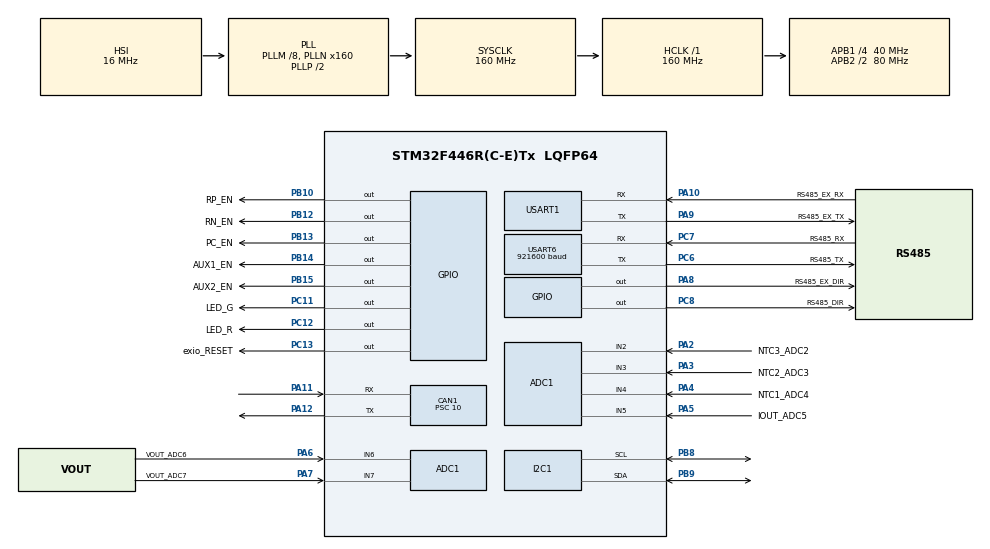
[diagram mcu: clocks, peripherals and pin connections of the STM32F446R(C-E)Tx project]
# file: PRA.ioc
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ADC1.Channel-0\#ChannelRegularConversion=ADC_CHANNEL_2
ADC1.Channel-1\#ChannelRegularConversion=ADC_CHANNEL_3
ADC1.Channel-2\#ChannelRegularConversion=ADC_CHANNEL_4
ADC1.Channel-3\#ChannelRegularConversion=ADC_CHANNEL_5
ADC1.Channel-4\#ChannelRegularConversion=ADC_CHANNEL_6
ADC1.Channel-5\#ChannelRegularConversion=ADC_CHANNEL_7
ADC1.ContinuousConvMode=ENABLE
ADC1.DMAContinuousRequests=ENABLE
ADC1.EOCSelection=ADC_EOC_SINGLE_CONV
ADC1.NbrOfConversion=6
ADC1.NbrOfConversionFlag=1
ADC1.Rank-0\#ChannelRegularConversion=1
ADC1.Rank-1\#ChannelRegularConversion=2
ADC1.Rank-2\#ChannelRegularConversion=3
ADC1.Rank-3\#ChannelRegularConversion=4
ADC1.Rank-4\#ChannelRegularConversion=5
ADC1.Rank-5\#ChannelRegularConversion=6
ADC1.SamplingTime-0\#ChannelRegularConversion=ADC_SAMPLETIME_480CYCLES
ADC1.SamplingTime-1\#ChannelRegularConversion=ADC_SAMPLETIME_480CYCLES
ADC1.SamplingTime-2\#ChannelRegularConversion=ADC_SAMPLETIME_480CYCLES
ADC1.SamplingTime-3\#ChannelRegularConversion=ADC_SAMPLETIME_15CYCLES
ADC1.SamplingTime-4\#ChannelRegularConversion=ADC_SAMPLETIME_15CYCLES
ADC1.SamplingTime-5\#ChannelRegularConversion=ADC_SAMPLETIME_15CYCLES
ADC1.ScanConvMode=ENABLE
ADC1.master=1
CAN1.BS1=CAN_BS1_11TQ
CAN1.BS2=CAN_BS2_4TQ
CAN1.CalculateBaudRate=250000
CAN1.CalculateTimeBit=4000
CAN1.CalculateTimeQuantum=250.0
CAN1.Mode=CAN_MODE_NORMAL
CAN1.Prescaler=10
CAN1.SJW=CAN_SJW_4TQ
Dma.ADC1.2.Direction=DMA_PERIPH_TO_MEMORY
Dma.ADC1.2.FIFOMode=DMA_FIFOMODE_DISABLE
Dma.ADC1.2.Instance=DMA2_Stream0
Dma.ADC1.2.MemDataAlignment=DMA_MDATAALIGN_HALFWORD
Dma.ADC1.2.MemInc=DMA_MINC_ENABLE
Dma.ADC1.2.Mode=DMA_CIRCULAR
Dma.ADC1.2.PeriphDataAlignment=DMA_PDATAALIGN_HALFWORD
Dma.ADC1.2.PeriphInc=DMA_PINC_DISABLE
Dma.ADC1.2.Priority=DMA_PRIORITY_LOW
Dma.Request0=USART6_RX
Dma.Request1=USART6_TX
Dma.Request2=ADC1
Dma.USART6_RX.0.Direction=DMA_PERIPH_TO_MEMORY
Dma.USART6_RX.0.FIFOMode=DMA_FIFOMODE_DISABLE
Dma.USART6_RX.0.Instance=DMA2_Stream1
Dma.USART6_RX.0.MemDataAlignment=DMA_MDATAALIGN_BYTE
Dma.USART6_RX.0.MemInc=DMA_MINC_ENABLE
Dma.USART6_RX.0.Mode=DMA_CIRCULAR
Dma.USART6_RX.0.PeriphDataAlignment=DMA_PDATAALIGN_BYTE
Dma.USART6_RX.0.PeriphInc=DMA_PINC_DISABLE
Dma.USART6_RX.0.Priority=DMA_PRIORITY_LOW
Dma.USART6_TX.1.Direction=DMA_MEMORY_TO_PERIPH
Dma.USART6_TX.1.FIFOMode=DMA_FIFOMODE_DISABLE
Dma.USART6_TX.1.Instance=DMA2_Stream6
Dma.USART6_TX.1.MemDataAlignment=DMA_MDATAALIGN_BYTE
Dma.USART6_TX.1.MemInc=DMA_MINC_ENABLE
Dma.USART6_TX.1.Mode=DMA_NORMAL
Dma.USART6_TX.1.PeriphDataAlignment=DMA_PDATAALIGN_BYTE
Dma.USART6_TX.1.PeriphInc=DMA_PINC_DISABLE
Dma.USART6_TX.1.Priority=DMA_PRIORITY_LOW
FREERTOS.Tasks01=defaultTask,24,512,StartDefaultTask,Default,NULL,Dynamic,NULL,NULL;rs485Task,8,512,Start_rs485,Default,NULL,Dynamic,NULL,NULL;controlTask,8,1024,StartControl,Default,NULL,Dynamic,NULL,NULL;systemTask,8,512,StartSystem,Default,NULL,Dynamic,NULL,NULL;can1Task,8,512,Start_can1,Default,NULL,Dynamic,NULL,NULL
FREERTOS.configTOTAL_HEAP_SIZE=30720
FREERTOS.configUSE_NEWLIB_REENTRANT=1
I2C1.I2C_Mode=I2C_Standard
Mcu.Family=STM32F4
Mcu.Name=STM32F446R(C-E)Tx
Mcu.Package=LQFP64
NVIC.ADC_IRQn=true\:5\:0\:false\:false\:true\:true\:true\:true\:true
NVIC.CAN1_RX0_IRQn=true\:5\:0\:false\:false\:true\:true\:true\:true\:true
NVIC.CAN1_SCE_IRQn=true\:5\:0\:false\:false\:true\:true\:true\:true\:true
NVIC.DMA2_Stream0_IRQn=true\:5\:0\:false\:false\:true\:true\:false\:true\:true
NVIC.DMA2_Stream1_IRQn=true\:5\:0\:false\:false\:true\:true\:false\:true\:true
NVIC.DMA2_Stream6_IRQn=true\:5\:0\:false\:false\:true\:true\:false\:true\:true
NVIC.PriorityGroup=NVIC_PRIORITYGROUP_4
NVIC.TIM6_DAC_IRQn=true\:15\:0\:false\:false\:true\:false\:false\:true\:true
NVIC.TimeBase=TIM6_DAC_IRQn
NVIC.TimeBaseIP=TIM6
NVIC.USART6_IRQn=true\:5\:0\:false\:false\:true\:true\:true\:true\:true
PA10.GPIO_Label=RS485_EX_RX
PA10.Mode=Asynchronous
PA10.Signal=USART1_RX
PA11.Mode=CAN_Activate
PA11.Signal=CAN1_RX
PA12.Mode=CAN_Activate
PA12.Signal=CAN1_TX
PA13.Mode=Trace_Asynchronous_SW
PA13.Signal=SYS_JTMS-SWDIO
PA14.Mode=Trace_Asynchronous_SW
PA14.Signal=SYS_JTCK-SWCLK
PA2.GPIO_Label=NTC3_ADC2
PA2.Signal=ADCx_IN2
PA3.GPIO_Label=NTC2_ADC3
PA3.Signal=ADCx_IN3
PA4.GPIO_Label=NTC1_ADC4
PA4.Signal=ADCx_IN4
PA5.GPIO_Label=IOUT_ADC5
PA5.Signal=ADCx_IN5
PA6.GPIO_Label=VOUT_ADC6
PA6.Signal=ADCx_IN6
PA7.GPIO_Label=VOUT_ADC7
PA7.Signal=ADCx_IN7
PA8.GPIO_Label=RS485_EX_DIR
PA8.Signal=GPIO_Output
PA9.GPIO_Label=RS485_EX_TX
PA9.Mode=Asynchronous
PA9.Signal=USART1_TX
PB10.GPIO_Label=RP_EN
PB10.Signal=GPIO_Output
PB12.GPIO_Label=RN_EN
PB12.Signal=GPIO_Output
PB13.GPIO_Label=PC_EN
PB13.Signal=GPIO_Output
PB14.GPIO_Label=AUX1_EN
PB14.Signal=GPIO_Output
PB15.GPIO_Label=AUX2_EN
PB15.Signal=GPIO_Output
PB3.Mode=Trace_Asynchronous_SW
PB3.Signal=SYS_JTDO-SWO
PB8.Mode=I2C
PB8.Signal=I2C1_SCL
PB9.Mode=I2C
PB9.Signal=I2C1_SDA
PC11.GPIO_Label=LED_G
PC11.Signal=GPIO_Output
PC12.GPIO_Label=LED_R
PC12.Signal=GPIO_Output
PC13.GPIO_Label=exio_RESET
PC13.Signal=GPIO_Output
PC6.GPIO_Label=RS485_TX
PC6.Mode=Asynchronous
PC6.Signal=USART6_TX
PC7.GPIO_Label=RS485_RX
PC7.Mode=Asynchronous
PC7.Signal=USART6_RX
PC8.GPIO_Label=RS485_DIR
PC8.Signal=GPIO_Output
ProjectManager.HeapSize=0x200
ProjectManager.StackSize=0x400
ProjectManager.TargetToolchain=STM32CubeIDE
RCC.AHBFreq_Value=160000000
RCC.APB1CLKDivider=RCC_HCLK_DIV4
RCC.APB1Freq_Value=40000000
RCC.APB1TimFreq_Value=80000000
RCC.APB2CLKDivider=RCC_HCLK_DIV2
RCC.APB2Freq_Value=80000000
RCC.APB2TimFreq_Value=160000000
RCC.CortexFreq_Value=160000000
RCC.HCLKFreq_Value=160000000
RCC.PLLM=8
RCC.PLLN=160
RCC.SYSCLKFreq_VALUE=160000000
RCC.SYSCLKSource=RCC_SYSCLKSOURCE_PLLCLK
RCC.USBFreq_Value=160000000
RCC.VCOOutputFreq_Value=320000000
SH.ADCx_IN2.0=ADC1_IN2,IN2
SH.ADCx_IN3.0=ADC1_IN3,IN3
SH.ADCx_IN4.0=ADC1_IN4,IN4
SH.ADCx_IN5.0=ADC1_IN5,IN5
SH.ADCx_IN6.0=ADC1_IN6,IN6
SH.ADCx_IN7.0=ADC1_IN7,IN7
USART1.VirtualMode=VM_ASYNC
USART6.BaudRate=921600
USART6.VirtualMode=VM_ASYNC
VP_FREERTOS_VS_CMSIS_V2.Mode=CMSIS_V2
VP_SYS_VS_tim6.Mode=TIM6
board=custom

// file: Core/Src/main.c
/* USER CODE BEGIN Header */
/**
  ******************************************************************************
  * @file           : main.c
  * @brief          : Main program body
  ******************************************************************************
  * @attention
  *
  * Copyright (c) 2025 STMicroelectronics.
  * All rights reserved.
  *
  * This software is licensed under terms that can be found in the LICENSE file
  * in the root directory of this software component.
  * If no LICENSE file comes with this software, it is provided AS-IS.
  *
  ******************************************************************************
  */
/* USER CODE END Header */
#include "main.h"
#include "cmsis_os.h"

/* USER CODE BEGIN Includes */

#include "rd_common.h"
#include "rd_define.h"

#include "rd_uart.h"
#include "rd_peripheral.h"
#include "rd_system.h"      /* RD_SYSTEM_INIT, RD_TASK_RS485, 전역 객체 (Step4) */
#include "rd_can_bms.h"
/* USER CODE END Includes */

ADC_HandleTypeDef hadc1;
DMA_HandleTypeDef hdma_adc1;

CAN_HandleTypeDef hcan1;

I2C_HandleTypeDef hi2c1;

UART_HandleTypeDef huart1;
UART_HandleTypeDef huart6;
DMA_HandleTypeDef hdma_usart6_rx;
DMA_HandleTypeDef hdma_usart6_tx;

/* Definitions for defaultTask */
osThreadId_t defaultTaskHandle;
const osThreadAttr_t defaultTask_attributes = {
  .name = "defaultTask",
  .stack_size = 512 * 4,
  .priority = (osPriority_t) osPriorityNormal,
};
/* Definitions for rs485Task */
osThreadId_t rs485TaskHandle;
const osThreadAttr_t rs485Task_attributes = {
  .name = "rs485Task",
  .stack_size = 512 * 4,
  .priority = (osPriority_t) osPriorityLow,
};
/* Definitions for controlTask */
osThreadId_t controlTaskHandle;
const osThreadAttr_t controlTask_attributes = {
  .name = "controlTask",
  .stack_size = 1024 * 4,
  .priority = (osPriority_t) osPriorityLow,
};
/* Definitions for systemTask */
osThreadId_t systemTaskHandle;
const osThreadAttr_t systemTask_attributes = {
  .name = "systemTask",
  .stack_size = 512 * 4,
  .priority = (osPriority_t) osPriorityLow,
};
/* Definitions for can1Task */
osThreadId_t can1TaskHandle;
const osThreadAttr_t can1Task_attributes = {
  .name = "can1Task",
  .stack_size = 512 * 4,
  .priority = (osPriority_t) osPriorityLow,
};

void SystemClock_Config(void);
static void MX_GPIO_Init(void);
static void MX_DMA_Init(void);
static void MX_ADC1_Init(void);
static void MX_CAN1_Init(void);
static void MX_USART1_UART_Init(void);
static void MX_USART6_UART_Init(void);
static void MX_I2C1_Init(void);
void StartDefaultTask(void *argument);
void Start_rs485(void *argument);
void StartControl(void *argument);
void StartSystem(void *argument);
void Start_can1(void *argument);

int main(void)
{

  /* MCU Configuration--------------------------------------------------------*/

  /* Reset of all peripherals, Initializes the Flash interface and the Systick. */
  HAL_Init();

  /* Configure the system clock */
  SystemClock_Config();

  /* Initialize all configured peripherals */
  MX_GPIO_Init();
  MX_DMA_Init();
  MX_ADC1_Init();
  MX_CAN1_Init();
  MX_USART1_UART_Init();
  MX_USART6_UART_Init();
  MX_I2C1_Init();
  /* USER CODE BEGIN 2 */
  RD_SYSTEM_INIT();   /* UART 바인딩 + 레지스터 맵/패킷 채널 INIT (스케줄러 시작 전 1회) */
  /* USER CODE END 2 */

  /* Init scheduler */
  osKernelInitialize();

  /* Create the thread(s) */
  /* creation of defaultTask */
  defaultTaskHandle = osThreadNew(StartDefaultTask, NULL, &defaultTask_attributes);

  /* creation of rs485Task */
  rs485TaskHandle = osThreadNew(Start_rs485, NULL, &rs485Task_attributes);

  /* creation of controlTask */
  controlTaskHandle = osThreadNew(StartControl, NULL, &controlTask_attributes);

  /* creation of systemTask */
  systemTaskHandle = osThreadNew(StartSystem, NULL, &systemTask_attributes);

  /* creation of can1Task */
  can1TaskHandle = osThreadNew(Start_can1, NULL, &can1Task_attributes);

  /* Start scheduler */
  osKernelStart();

  /* We should never get here as control is now taken by the scheduler */

  /* Infinite loop */
  while (1)
  {

  }
}

void SystemClock_Config(void)
{
  RCC_OscInitTypeDef RCC_OscInitStruct = {0};
  RCC_ClkInitTypeDef RCC_ClkInitStruct = {0};

  /** Configure the main internal regulator output voltage
  */
  __HAL_RCC_PWR_CLK_ENABLE();
  __HAL_PWR_VOLTAGESCALING_CONFIG(PWR_REGULATOR_VOLTAGE_SCALE1);

  /** Initializes the RCC Oscillators according to the specified parameters
  * in the RCC_OscInitTypeDef structure.
  */
  RCC_OscInitStruct.OscillatorType = RCC_OSCILLATORTYPE_HSI;
  RCC_OscInitStruct.HSIState = RCC_HSI_ON;
  RCC_OscInitStruct.HSICalibrationValue = RCC_HSICALIBRATION_DEFAULT;
  RCC_OscInitStruct.PLL.PLLState = RCC_PLL_ON;
  RCC_OscInitStruct.PLL.PLLSource = RCC_PLLSOURCE_HSI;
  RCC_OscInitStruct.PLL.PLLM = 8;
  RCC_OscInitStruct.PLL.PLLN = 160;
  RCC_OscInitStruct.PLL.PLLP = RCC_PLLP_DIV2;
  RCC_OscInitStruct.PLL.PLLQ = 2;
  RCC_OscInitStruct.PLL.PLLR = 2;
  if (HAL_RCC_OscConfig(&RCC_OscInitStruct) != HAL_OK)
  {
    Error_Handler();
  }

  /** Initializes the CPU, AHB and APB buses clocks
  */
  RCC_ClkInitStruct.ClockType = RCC_CLOCKTYPE_HCLK|RCC_CLOCKTYPE_SYSCLK
                              |RCC_CLOCKTYPE_PCLK1|RCC_CLOCKTYPE_PCLK2;
  RCC_ClkInitStruct.SYSCLKSource = RCC_SYSCLKSOURCE_PLLCLK;
  RCC_ClkInitStruct.AHBCLKDivider = RCC_SYSCLK_DIV1;
  RCC_ClkInitStruct.APB1CLKDivider = RCC_HCLK_DIV4;
  RCC_ClkInitStruct.APB2CLKDivider = RCC_HCLK_DIV2;

  if (HAL_RCC_ClockConfig(&RCC_ClkInitStruct, FLASH_LATENCY_5) != HAL_OK)
  {
    Error_Handler();
  }
}

static void MX_ADC1_Init(void)
{

  ADC_ChannelConfTypeDef sConfig = {0};

  /** Configure the global features of the ADC (Clock, Resolution, Data Alignment and number of conversion)
  */
  hadc1.Instance = ADC1;
  hadc1.Init.ClockPrescaler = ADC_CLOCK_SYNC_PCLK_DIV4;
  hadc1.Init.Resolution = ADC_RESOLUTION_12B;
  hadc1.Init.ScanConvMode = ENABLE;
  hadc1.Init.ContinuousConvMode = ENABLE;
  hadc1.Init.DiscontinuousConvMode = DISABLE;
  hadc1.Init.ExternalTrigConvEdge = ADC_EXTERNALTRIGCONVEDGE_NONE;
  hadc1.Init.ExternalTrigConv = ADC_SOFTWARE_START;
  hadc1.Init.DataAlign = ADC_DATAALIGN_RIGHT;
  hadc1.Init.NbrOfConversion = 6;
  hadc1.Init.DMAContinuousRequests = ENABLE;
  hadc1.Init.EOCSelection = ADC_EOC_SINGLE_CONV;
  if (HAL_ADC_Init(&hadc1) != HAL_OK)
  {
    Error_Handler();
  }

  /** Configure for the selected ADC regular channel its corresponding rank in the sequencer and its sample time.
  */
  sConfig.Channel = ADC_CHANNEL_2;
  sConfig.Rank = 1;
  sConfig.SamplingTime = ADC_SAMPLETIME_480CYCLES;
  if (HAL_ADC_ConfigChannel(&hadc1, &sConfig) != HAL_OK)
  {
    Error_Handler();
  }

  /** Configure for the selected ADC regular channel its corresponding rank in the sequencer and its sample time.
  */
  sConfig.Channel = ADC_CHANNEL_3;
  sConfig.Rank = 2;
  if (HAL_ADC_ConfigChannel(&hadc1, &sConfig) != HAL_OK)
  {
    Error_Handler();
  }

  /** Configure for the selected ADC regular channel its corresponding rank in the sequencer and its sample time.
  */
  sConfig.Channel = ADC_CHANNEL_4;
  sConfig.Rank = 3;
  if (HAL_ADC_ConfigChannel(&hadc1, &sConfig) != HAL_OK)
  {
    Error_Handler();
  }

  /** Configure for the selected ADC regular channel its corresponding rank in the sequencer and its sample time.
  */
  sConfig.Channel = ADC_CHANNEL_5;
  sConfig.Rank = 4;
  sConfig.SamplingTime = ADC_SAMPLETIME_15CYCLES;
  if (HAL_ADC_ConfigChannel(&hadc1, &sConfig) != HAL_OK)
  {
    Error_Handler();
  }

  /** Configure for the selected ADC regular channel its corresponding rank in the sequencer and its sample time.
  */
  sConfig.Channel = ADC_CHANNEL_6;
  sConfig.Rank = 5;
  if (HAL_ADC_ConfigChannel(&hadc1, &sConfig) != HAL_OK)
  {
    Error_Handler();
  }

  /** Configure for the selected ADC regular channel its corresponding rank in the sequencer and its sample time.
  */
  sConfig.Channel = ADC_CHANNEL_7;
  sConfig.Rank = 6;
  if (HAL_ADC_ConfigChannel(&hadc1, &sConfig) != HAL_OK)
  {
    Error_Handler();
  }

}

static void MX_CAN1_Init(void)
{

  hcan1.Instance = CAN1;
  hcan1.Init.Prescaler = 10;
  hcan1.Init.Mode = CAN_MODE_NORMAL;
  hcan1.Init.SyncJumpWidth = CAN_SJW_4TQ;
  hcan1.Init.TimeSeg1 = CAN_BS1_11TQ;
  hcan1.Init.TimeSeg2 = CAN_BS2_4TQ;
  hcan1.Init.TimeTriggeredMode = DISABLE;
  hcan1.Init.AutoBusOff = DISABLE;
  hcan1.Init.AutoWakeUp = DISABLE;
  hcan1.Init.AutoRetransmission = DISABLE;
  hcan1.Init.ReceiveFifoLocked = DISABLE;
  hcan1.Init.TransmitFifoPriority = DISABLE;
  if (HAL_CAN_Init(&hcan1) != HAL_OK)
  {
    Error_Handler();
  }

}

static void MX_I2C1_Init(void)
{

  hi2c1.Instance = I2C1;
  hi2c1.Init.ClockSpeed = 100000;
  hi2c1.Init.DutyCycle = I2C_DUTYCYCLE_2;
  hi2c1.Init.OwnAddress1 = 0;
  hi2c1.Init.AddressingMode = I2C_ADDRESSINGMODE_7BIT;
  hi2c1.Init.DualAddressMode = I2C_DUALADDRESS_DISABLE;
  hi2c1.Init.OwnAddress2 = 0;
  hi2c1.Init.GeneralCallMode = I2C_GENERALCALL_DISABLE;
  hi2c1.Init.NoStretchMode = I2C_NOSTRETCH_DISABLE;
  if (HAL_I2C_Init(&hi2c1) != HAL_OK)
  {
    Error_Handler();
  }

}

static void MX_USART1_UART_Init(void)
{

  huart1.Instance = USART1;
  huart1.Init.BaudRate = 115200;
  huart1.Init.WordLength = UART_WORDLENGTH_8B;
  huart1.Init.StopBits = UART_STOPBITS_1;
  huart1.Init.Parity = UART_PARITY_NONE;
  huart1.Init.Mode = UART_MODE_TX_RX;
  huart1.Init.HwFlowCtl = UART_HWCONTROL_NONE;
  huart1.Init.OverSampling = UART_OVERSAMPLING_16;
  if (HAL_UART_Init(&huart1) != HAL_OK)
  {
    Error_Handler();
  }

}

static void MX_USART6_UART_Init(void)
{

  huart6.Instance = USART6;
  huart6.Init.BaudRate = 921600;
  huart6.Init.WordLength = UART_WORDLENGTH_8B;
  huart6.Init.StopBits = UART_STOPBITS_1;
  huart6.Init.Parity = UART_PARITY_NONE;
  huart6.Init.Mode = UART_MODE_TX_RX;
  huart6.Init.HwFlowCtl = UART_HWCONTROL_NONE;
  huart6.Init.OverSampling = UART_OVERSAMPLING_16;
  if (HAL_UART_Init(&huart6) != HAL_OK)
  {
    Error_Handler();
  }

}

static void MX_DMA_Init(void)
{

  /* DMA controller clock enable */
  __HAL_RCC_DMA2_CLK_ENABLE();

  /* DMA interrupt init */
  /* DMA2_Stream0_IRQn interrupt configuration */
  HAL_NVIC_SetPriority(DMA2_Stream0_IRQn, 5, 0);
  HAL_NVIC_EnableIRQ(DMA2_Stream0_IRQn);
  /* DMA2_Stream1_IRQn interrupt configuration */
  HAL_NVIC_SetPriority(DMA2_Stream1_IRQn, 5, 0);
  HAL_NVIC_EnableIRQ(DMA2_Stream1_IRQn);
  /* DMA2_Stream6_IRQn interrupt configuration */
  HAL_NVIC_SetPriority(DMA2_Stream6_IRQn, 5, 0);
  HAL_NVIC_EnableIRQ(DMA2_Stream6_IRQn);

}

static void MX_GPIO_Init(void)
{
  GPIO_InitTypeDef GPIO_InitStruct = {0};

  /* GPIO Ports Clock Enable */
  __HAL_RCC_GPIOC_CLK_ENABLE();
  __HAL_RCC_GPIOA_CLK_ENABLE();
  __HAL_RCC_GPIOB_CLK_ENABLE();

  /*Configure GPIO pin Output Level */
  HAL_GPIO_WritePin(GPIOC, exio_RESET_Pin|RS485_DIR_Pin|LED_G_Pin|LED_R_Pin, GPIO_PIN_RESET);

  /*Configure GPIO pin Output Level */
  HAL_GPIO_WritePin(GPIOB, RP_EN_Pin|RN_EN_Pin|PC_EN_Pin|AUX1_EN_Pin
                          |AUX2_EN_Pin, GPIO_PIN_RESET);

  /*Configure GPIO pin Output Level */
  HAL_GPIO_WritePin(RS485_EX_DIR_GPIO_Port, RS485_EX_DIR_Pin, GPIO_PIN_RESET);

  /*Configure GPIO pins : exio_RESET_Pin RS485_DIR_Pin LED_G_Pin LED_R_Pin */
  GPIO_InitStruct.Pin = exio_RESET_Pin|RS485_DIR_Pin|LED_G_Pin|LED_R_Pin;
  GPIO_InitStruct.Mode = GPIO_MODE_OUTPUT_PP;
  GPIO_InitStruct.Pull = GPIO_NOPULL;
  GPIO_InitStruct.Speed = GPIO_SPEED_FREQ_LOW;
  HAL_GPIO_Init(GPIOC, &GPIO_InitStruct);

  /*Configure GPIO pins : RP_EN_Pin RN_EN_Pin PC_EN_Pin AUX1_EN_Pin
                           AUX2_EN_Pin */
  GPIO_InitStruct.Pin = RP_EN_Pin|RN_EN_Pin|PC_EN_Pin|AUX1_EN_Pin
                          |AUX2_EN_Pin;
  GPIO_InitStruct.Mode = GPIO_MODE_OUTPUT_PP;
  GPIO_InitStruct.Pull = GPIO_NOPULL;
  GPIO_InitStruct.Speed = GPIO_SPEED_FREQ_LOW;
  HAL_GPIO_Init(GPIOB, &GPIO_InitStruct);

  /*Configure GPIO pin : RS485_EX_DIR_Pin */
  GPIO_InitStruct.Pin = RS485_EX_DIR_Pin;
  GPIO_InitStruct.Mode = GPIO_MODE_OUTPUT_PP;
  GPIO_InitStruct.Pull = GPIO_NOPULL;
  GPIO_InitStruct.Speed = GPIO_SPEED_FREQ_LOW;
  HAL_GPIO_Init(RS485_EX_DIR_GPIO_Port, &GPIO_InitStruct);

}

void StartDefaultTask(void *argument)
{
  /* USER CODE BEGIN 5 */
  RD_TASK_DEFAULT();
  /* USER CODE END 5 */
}

void Start_rs485(void *argument)
{
  /* USER CODE BEGIN Start_rs485 */
  RD_TASK_RS485();   /* 내부 init + 이벤트 for(;;) 루프 (ECU/DPC_B/PRA 구조) */
  /* USER CODE END Start_rs485 */
}

void StartControl(void *argument)
{
  /* USER CODE BEGIN StartControl */
  /* Infinite loop */
	RD_TASK_CONTROL();
  /* USER CODE END StartControl */
}

void StartSystem(void *argument)
{
  /* USER CODE BEGIN StartSystem */
  RD_TASK_SYSTEM();   /* 10ms Checker/EVALUATE/PUBLISH (내부 for(;;)) — Step6 */
  /* USER CODE END StartSystem */
}

void Start_can1(void *argument)
{
  /* USER CODE BEGIN Start_can1 */
  RD_TASK_CAN();
  /* USER CODE END Start_can1 */
}

void HAL_TIM_PeriodElapsedCallback(TIM_HandleTypeDef *htim)
{
  if (htim->Instance == TIM6)
  {
    HAL_IncTick();
  }
}

void Error_Handler(void)
{
  __disable_irq();
  while (1)
  {
  }
}
